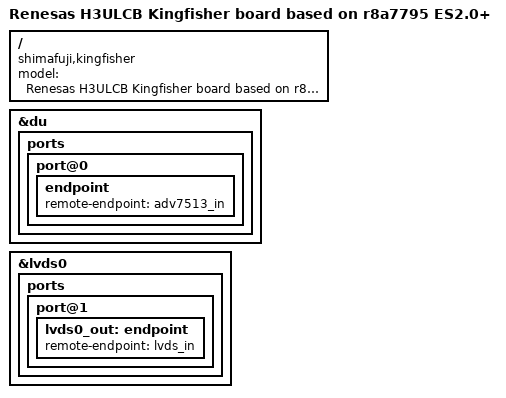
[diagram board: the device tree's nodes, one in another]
// SPDX-License-Identifier: GPL-2.0
/*
 * Device Tree Source for the H3ULCB Kingfisher board
 *
 * Copyright (C) 2017 Renesas Electronics Corp.
 * Copyright (C) 2017 Cogent Embedded, Inc.
 */

#include "r8a7795-h3ulcb.dts"
#include "ulcb-kf.dtsi"

/ {
	model = "Renesas H3ULCB Kingfisher board based on r8a7795 ES2.0+";
	compatible = "shimafuji,kingfisher", "renesas,h3ulcb",
		     "renesas,r8a7795";
};

&du {
	ports {
		port@0 {
			endpoint {
				remote-endpoint = <&adv7513_in>;
			};
		};
	};
};

&lvds0 {
	status = "okay";

	ports {
		port@1 {
			lvds0_out: endpoint {
				remote-endpoint = <&lvds_in>;
			};
		};
	};
};

/* use CN11 instead default CN29/CN48 (H3 only) */
//#include "ulcb-kf-cn11.dtsi"
